# RZT2ME register map
Vendor: Renesas Electronics Corporation; Series: RZT; File version: 1.00.00
CPU: other r0p0, little endian, MPU, no FPU, VTOR, 4 interrupt priority bits, 624 interrupts
Registers are 32-bit, read-write, reset 0x0 unless marked. A register's access mark holds for its fields unless they carry their own. Offsets are from the block's base; [hi:lo] are bit positions; {n}, {i} and the like mark numbered series; 'fields as' and 'values as' point back to an identical list.

## DSMIF0 — Delta-sigma Interface 0
Base 0x90008000
Same registers: DSMIF1 0x90008400
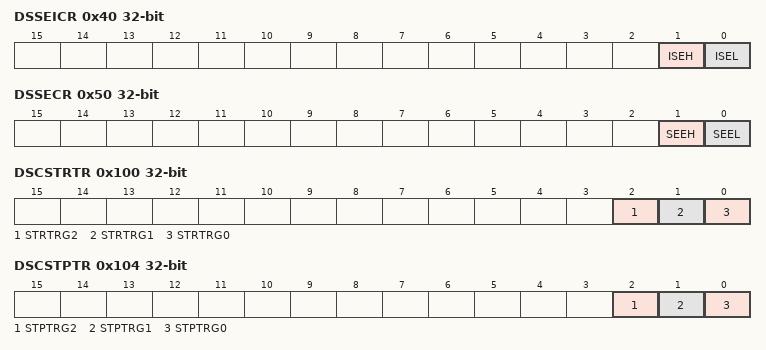
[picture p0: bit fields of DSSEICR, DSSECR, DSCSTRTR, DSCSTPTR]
0x40 DSSEICR — Overcurrent Sum Error Detect Interrupt Control Register
  [1] ISEH — Overcurrent sum error upper limit detection interrupt enable bit
    0=Do not output overcurrent sum error upper limit detection interrupt; 1=Overcurrent sum error lower upper detection interrupt can be output
  [0] ISEL — Overcurrent sum error lower limit detection interrupt enable bit
    0=Do not output overcurrent sum error lower limit detection interrupt; 1=Overcurrent sum error lower limit detection interrupt can be output
0x44 DSSECSR — Overcurrent Sum Error Detect Channel Setting Register
  [2:0] SEDM — Overcurrent sum error detect mode setting bit
    0=Detects error of sum value of overcurrent data of CH0, CH1, CH2; 1=Detects error of sum value of overcurrent data of CH0, CH1; 2=Detects error of overcurrent data of CH0; 3=Detects error of overcurrent data of CH1; 4=Detects error of overcurrent data of CH2; other=Others (Setting prohibited (detects error of sum value of overcurrent data of CH0, CH1, CH2))
0x48 DSSELTR — Overcurrent Sum Error Detect Low Threshold Register
  [17:0] SCMPTBL — Overcurrent sum error detect lower limit
0x4C DSSEHTR — Overcurrent Sum Error Detect High Threshold Register
  [17:0] SCMPTBH — Overcurrent sum error detect upper limit
0x50 DSSECR — Overcurrent Sum Error Detect Control Register
  [1] SEEH — Overcurrent sum error upper limit detection enable bit
    0=The upper limit exceeded detection function of overcurrent sum error detection is invalid; 1=The upper limit exceeded detection function of overcurrent sum error detection is valid
  [0] SEEL — Overcurrent sum error lower limit detection enable bit
    0=The lower limit exceeded detection function of overcurrent sum error detection is invalid; 1=The lower limit exceeded detection function of overcurrent sum error detection is valid
{0x60+4i} DSSECDR{i} (i=0..2) — Overcurrent Sum Error Detect Capture Data Register {i}
  [15:0] SECDR — Overcurrent sum error detect capture data n
0x100 DSCSTRTR — Channel Software Start Trigger Register
  [all] fields
    0=Do nothing; 1=Start channel
  [2] STRTRG2 — Channel 2 start trigger
  [1] STRTRG1 — Channel 1 start trigger
  [0] STRTRG0 — Channel 0 start trigger
0x104 DSCSTPTR — Channel Software Stop Trigger Register
  [all] fields
    0=Do nothing; 1=Stop channel
  [2] STPTRG2 — Channel 2 stop trigger
  [1] STPTRG1 — Channel 1 stop trigger
  [0] STPTRG0 — Channel 0 stop trigger
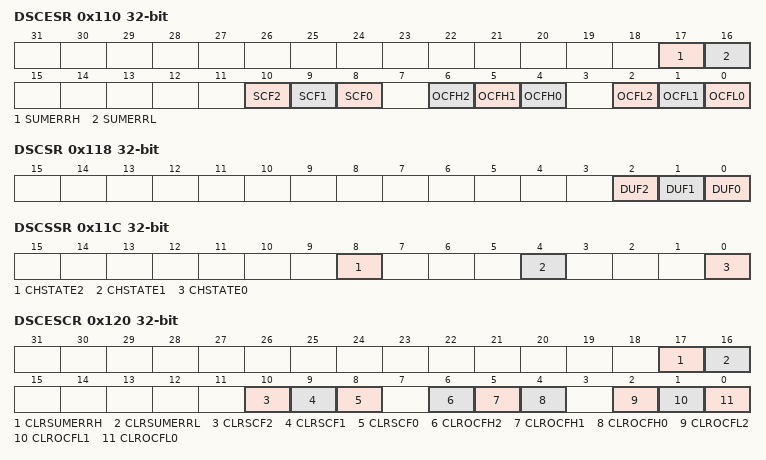
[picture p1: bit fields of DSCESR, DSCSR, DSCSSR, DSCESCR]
0x110 DSCESR ro — Channel Error Status Register
  [17] SUMERRH — Overcurrent sum error upper limit detection flag
    0=Indicates that the sum value of overcurrent data is not more than the upper limit; 1=Indicates that the sum value of overcurrent data is more than the upper limit
  [16] SUMERRL — Overcurrent sum error lower limit detection flag
    0=Indicates that the sum value of overcurrent data is not less than the lower limit; 1=Indicates that the sum value of overcurrent data is less than the lower limit
  [10] SCF2 — Channel 2 short circuit detection flag
    0=Indicates that the MDAT2 pin short circuit is not detected; 1=Indicates that a short circuit on the MDAT2 pin has been detected
  [9] SCF1 — Channel 1 short circuit detection flag
    0=Indicates that the MDAT1 pin short circuit is not detected; 1=Indicates that a short circuit on the MDAT1 pin has been detected
  [8] SCF0 — Channel 0 short circuit detection flag
    0=Indicates that the MDAT0 pin short circuit is not detected; 1=Indicates that a short circuit on the MDAT0 pin has been detected
  [6] OCFH2 — Channel 2 overcurrent upper limit detection flag
    0=Indicates that the overcurrent data is not more than the upper limit; 1=Indicates that the overcurrent data is more than the upper limit
  [5] OCFH1 — Channel 1 overcurrent upper limit detection flag
    values as OCFH2
  [4] OCFH0 — Channel 0 overcurrent upper limit detection flag
    values as OCFH2
  [2] OCFL2 — Channel 2 overcurrent lower limit detection flag
    0=Indicates that the overcurrent data is not less than the lower limit; 1=Indicates that the overcurrent data is less than the lower limit
  [1] OCFL1 — Channel 1 overcurrent lower limit detection flag
    values as OCFL2
  [0] OCFL0 — Channel 0 overcurrent lower limit detection flag
    values as OCFL2
0x118 DSCSR ro — Channel Status Register
  [all] fields
    0=Indicates that the Current Data register has not been updated; 1=Indicates that the Current Data register has been updated
  [2] DUF2 — Channel 2 Data Update flag
  [1] DUF1 — Channel 1 Data Update flag
  [0] DUF0 — Channel 0 Data Update flag
0x11C DSCSSR ro — Channel State Status Register
  [all] fields
    0=Channel stop; 1=Channel in operation
  [8] CHSTATE2 — Channel 2 state
  [4] CHSTATE1 — Channel 1 state
  [0] CHSTATE0 — Channel 0 state
0x120 DSCESCR wo — Channel Error Status Clear Register
  [17] CLRSUMERRH — Overcurrent Sum Error Upper Limit Detection Flag Clear
    0=No effect; 1=Clear DSCESR.SUMERRH
  [16] CLRSUMERRL — Overcurrent Sum Error Lower Limit Detection Flag Clear
    0=No effect; 1=Clear DSCESR.SUMERRL
  [10] CLRSCF2 — Channel 2 Short Circuit Detection Flag Clear
    0=No effect; 1=Clear DSCESR.SCF2 / DSCSRCH2.SCF
  [9] CLRSCF1 — Channel 1 Short Circuit Detection Flag Clear
    0=No effect; 1=Clear DSCESR.SCF1 / DSCSRCH1.SCF
  [8] CLRSCF0 — Channel 0 Short Circuit Detection Flag Clear
    0=No effect; 1=Clear DSCESR.SCF0 / DSCSRCH0.SCF
  [6] CLROCFH2 — Channel 2 Overcurrent Upper Limit Detection Flag Clear
    0=No effect; 1=Clear DSCESR.OCFH2 / DSCSRCH2.OCFH
  [5] CLROCFH1 — Channel 1 Overcurrent Upper Limit Detection Flag Clear
    0=No effect; 1=Clear DSCESR.OCFH1 / DSCSRCH1.OCFH
  [4] CLROCFH0 — Channel 0 Overcurrent Upper Limit Detection Flag Clear
    0=No effect; 1=Clear DSCESR.OCFH0 / DSCSRCH0.OCFH
  [2] CLROCFL2 — Channel 2 Overcurrent Lower Limit Detection Flag Clear
    0=No effect; 1=Clear DSCESR.OCFL2 / DSCSRCH2.OCFL
  [1] CLROCFL1 — Channel 1 Overcurrent Lower Limit Detection Flag Clear
    0=No effect; 1=Clear DSCESR.OCFL1 / DSCSRCH1.OCFL
  [0] CLROCFL0 — Channel 0 Overcurrent Lower Limit Detection Flag Clear
    0=No effect; 1=Clear DSCESR.OCFL0 / DSCSRCH0.OCFL
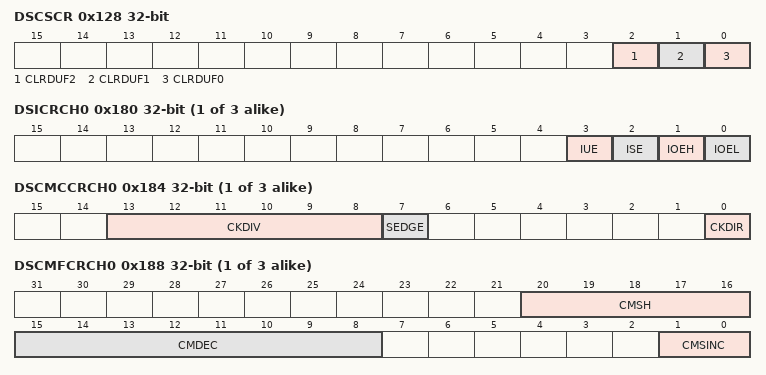
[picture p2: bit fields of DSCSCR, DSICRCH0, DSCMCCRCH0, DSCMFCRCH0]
0x128 DSCSCR wo — Channel Status Clear Register
  [2] CLRDUF2 — Channel 2 Data Update Flag Clear
    0=No effect; 1=Clear DSCSR.DUF2 / DSCSRCH2.DUF
  [1] CLRDUF1 — Channel 1 Data Update Flag Clear
    0=No effect; 1=Clear DSCSR.DUF1 / DSCSRCH1.DUF
  [0] CLRDUF0 — Channel 0 Data Update Flag Clear
    0=No effect; 1=Clear DSCSR.DUF0 / DSCSRCH0.DUF
{0x180+0x90*i} DSICRCH{i} (i=0..2) — Interrupt Control Register Channel {i}
  [3] IUE — Current data register update interrupt enable
    0=Do not output current data register update interrupt; 1=Current data register update interrupt can be output
  [2] ISE — Short circuit detection error interrupt enable
    0=Do not output short circuit detection interrupt; 1=Short circuit detection interrupt can be output
  [1] IOEH — Overcurrent upper limit exceeded output interrupt enable
    0=Do not output overcurrent upper limit detection interrupt; 1=Overcurrent upper limit exceeded detection interrupt can be output
  [0] IOEL — Overcurrent lower limit detection interrupt enable
    0=Do not output overcurrent lower limit detection interrupt; 1=Overcurrent lower limit detection interrupt can be output
{0x184+0x90*i} DSCMCCRCH{i} (i=0..2) — Current Measurement Clock Control Register Channel {i}
  [13:8] CKDIV — A/D conversion clock division ratio
  [7] SEDGE — Sampling edge selection
    0=Capture MDATn at the negative edge of MCLKn; 1=Capture MDATn at the positive edge of MCLKn
  [0] CKDIR — A/D conversion clock master/slave switching
    0=MCLKn pin is input (slave operation); 1=MCLKn pin is output (master operation)
{0x188+0x90*i} DSCMFCRCH{i} (i=0..2) — Current Measurement Filter Control Register Channel {i}
  [20:16] CMSH — Data shift setting for current measurement
    0=[23:8]; 1=[22:7]; 2=[21:6]; 3=[20:5]; 4=[19:4]; 5=[18:3]; 6=[17:2]; 7=[16:1]; 8=[15:0]; 9=[14:0]<<1; 10=[13:0]<<2; 11=[12:0]<<3; 12=[11:0]<<4; 13=[10:0]<<5; 14=[9:0]<<6; 15=[8:0]<<7; 16=[7:0]<<8; 17=[6:0]<<9; 18=[5:0]<<10; 19=[4:0]<<11; other=Others (Setting prohibited)
  [15:8] CMDEC — Decimation ratio selection for current measurement
  [1:0] CMSINC — Current measurement filter order setting
    0=Sinc3 (3rd order); 1=Sinc1 (1st order); 2=Sinc2 (2nd order); 3=Setting prohibited
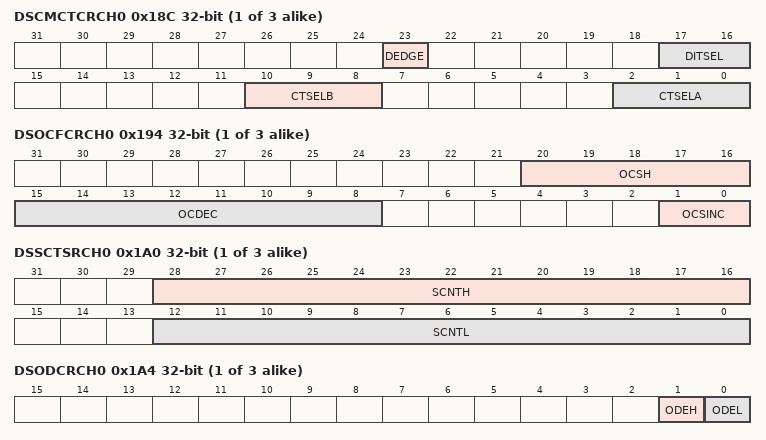
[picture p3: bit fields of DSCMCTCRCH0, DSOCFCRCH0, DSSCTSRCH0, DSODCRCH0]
{0x18C+0x90*i} DSCMCTCRCH{i} (i=0..2) — Current Measurement Capture Trigger Control Register Channel {i}
  [23] DEDGE — Current measurement filter initialization trigger for division counter for decimation edge selection bit. The trigger from ELC is usually used positive edge. Change from the initial value if necessary.
    0=The frequency division counter for decimation is initialized at the negative edge of initialization trigger; 1=The frequency division counter for decimation is initialized at the positive edge of initialization trigger
  [17:16] DITSEL — Current measurement filter initialization trigger selection bit for frequency division counter for decimation.
    0=Do not initialize; 1=Select decimation dividing counter initialization trigger 0; 2=Select decimation dividing counter initialization trigger 1; 3=Select decimation dividing counter initialization trigger 2
  [10:8] CTSELB — Current capture trigger B selection bit
    0=Do not capture; {v}=Select current data capture trigger {v-1} (v=1..6); 7=Setting prohibited (do not capture)
  [2:0] CTSELA — Current capture trigger A selection bit
    values as CTSELB
{0x190+0x90*i} DSEDCRCH{i} (i=0..2) — Error Detect Control Register Channel {i}
  [0] SDE — Short circuit detection enable bit
    0=Short circuit detection is invalid; 1=Short circuit detection is valid
{0x194+0x90*i} DSOCFCRCH{i} (i=0..2) — Overcurrent Detect Filter Control Register Channel {i}
  [20:16] OCSH — Data shift setting for overcurrent detection
    values as DSCMFCRCH0.CMSH
  [15:8] OCDEC — Decimation ratio selection for overcurrent detection
  [1:0] OCSINC — Overcurrent detection filter order setting
    values as DSCMFCRCH0.CMSINC
{0x198+0x90*i} DSOCLTRCH{i} (i=0..2) — Overcurrent Low Threshold Register Channel {i}
  [15:0] OCMPTBL — Overcurrent detection lower limit
{0x19C+0x90*i} DSOCHTRCH{i} (i=0..2) — Overcurrent High Threshold Register Channel {i}
  [15:0] OCMPTBH — Overcurrent detection upper limit
{0x1A0+0x90*i} DSSCTSRCH{i} (i=0..2) — Short Circuit Threshold Setting Register Channel {i}
  [28:16] SCNTH — Short circuit detection high continuous detection count
  [12:0] SCNTL — Short circuit detection low continuous detection count
{0x1A4+0x90*i} DSODCRCH{i} (i=0..2) — Overcurrent Detect Control Register Channel {i}
  [1] ODEH — Overcurrent upper limit exceeded detection enable bit
    0=Overcurrent upper limit exceeded detection is invalid; 1=Overcurrent upper limit exceeded detection is valid
  [0] ODEL — Overcurrent lower limit detection enable bit
    0=Overcurrent lower limit detection is invalid; 1=Overcurrent lower limit detection is valid
{0x1C0+0x90*i} DSCSTRTRCH{i} (i=0..2) — Software Start Trigger Register Channel {i}
  [0] STRTRG — Channel start trigger
    0=Do nothing; 1=Start channel n
{0x1C4+0x90*i} DSCSTPTRCH{i} (i=0..2) — Software Stop Trigger Register Channel {i}
  [0] STPTRG — Channel stop trigger
    0=Do nothing; 1=Stop channel n
{0x1D0+0x90*i} DSCDRCH{i} (i=0..2) ro — Current Data Register Channel {i}
  [15:0] ADDR — Current data
{0x1D4+0x90*i} DSCCDRACH{i} (i=0..2) ro — Capture Current Data Register A Channel {i}
  [15:0] CDRA — Capture current data A
{0x1D8+0x90*i} DSCCDRBCH{i} (i=0..2) ro — Capture Current Data Register B Channel {i}
  [15:0] CDRB — Capture current data B
{0x1DC+0x90*i} DSOCDRCH{i} (i=0..2) ro — Overcurrent Data Register Channel {i}
  [15:0] ODR — Overcurrent data
{0x1E0+0x90*i} DSCOCDRCH{i} (i=0..2) ro — Capture Overcurrent Data Register Channel {i}
  [15:0] CODR — Capture Overcurrent data when overcurrent detected
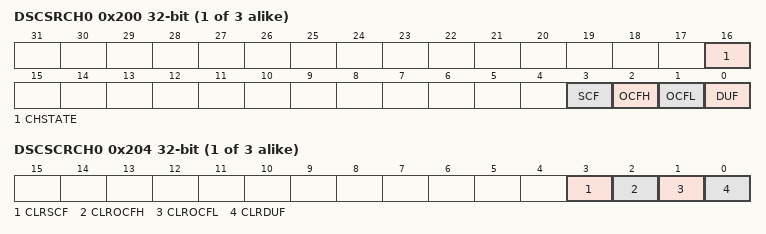
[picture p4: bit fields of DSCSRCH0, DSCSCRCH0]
{0x200+0x90*i} DSCSRCH{i} (i=0..2) ro — Status Register Channel {i}
  [16] CHSTATE — Channel n state
    0=Channel stop; 1=Channel in operation
  [3] SCF — Channel n short circuit detection flag
    0=Indicates that the MDATn pin short circuit is not detected; 1=Indicates that a short circuit on the MDATn pin has been detected
  [2] OCFH — Channel n overcurrent upper limit exceeded flag
    0=Indicates that the overcurrent data does not exceed the upper limit; 1=Indicates that the overcurrent data has exceeded the upper limit
  [1] OCFL — Channel n overcurrent lower limit detection flag
    0=Indicates that the overcurrent data is not less than the lower limit; 1=Indicates that the overcurrent data has fallen the lower limit
  [0] DUF — Channel n data update flag
    0=Indicates that the current data register has not been updated; 1=Indicates that the current data register has been updated
{0x204+0x90*i} DSCSCRCH{i} (i=0..2) — Status Clear Register Channel {i}
  [3] CLRSCF — Channel n short circuit detection flag clear
    0=Do nothing; 1=Clear DSCESR.SCFn / DSCSRCHn.SCF
  [2] CLROCFH — Channel n overcurrent upper limit exceeded flag clear
    0=Do nothing; 1=Clear DSCESR.OCFHn / DSCSRCHn.OCFH
  [1] CLROCFL — Channel n overcurrent lower limit detection flag clear
    0=Do nothing; 1=Clear DSCESR.OCFLn / DSCSRCHn.OCFL
  [0] CLRDUF — Channel n data update flag clear
    0=Do nothing; 1=Clear DSCSR.DUFn / DSCSRCHn.DUF
